# MCU_CPSW0_NUSS_CPTS_ register map
Vendor: Texas Instruments
Peripheral module from a debugger description file (folder am65x).
Registers are 32-bit, read-write, reset 0x0 unless marked. A register's access mark holds for its fields unless they carry their own. Offsets are as the file gives them; lines under a group give offsets from that group; [hi:lo] are bit positions; {n}, {i} and the like mark numbered series; 'fields as' and 'values as' point back to an identical list; <NAME> marks a mode.

## MCU_CPSW0_NUSS_CPTS
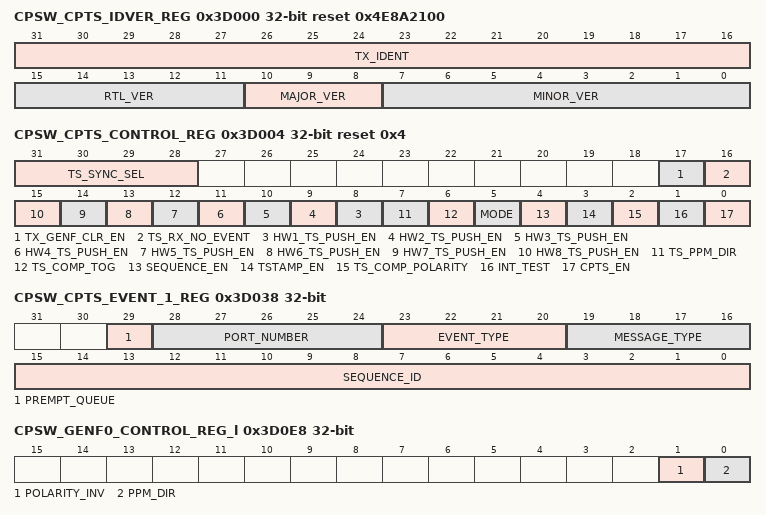
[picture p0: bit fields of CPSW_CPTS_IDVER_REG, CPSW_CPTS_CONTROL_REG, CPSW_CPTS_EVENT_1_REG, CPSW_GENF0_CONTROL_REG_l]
0x3D000 CPSW_CPTS_IDVER_REG ro reset 0x4E8A2100 (reset mask 0xFFFFFF00) — MCU_CPSW0_NUSS_CPTS Identification and Version Register
  [31:16] TX_IDENT — TX Identification Value
  [15:11] RTL_VER — RTL version value
  [10:8] MAJOR_VER — Major Version Value
  [7:0] MINOR_VER — Minor Version Value SR2.0: Bh SR1.0: 9h
0x3D004 CPSW_CPTS_CONTROL_REG reset 0x4 — Time Sync Control Register
  [31:28] TS_SYNC_SEL — TS_SYNC output time stamp counter bit select
  [17] TX_GENF_CLR_EN — GENF (and ESTF) Clear Enable. 0 = A TS_GENFn output is not cleared when the associated 1 = A TS_GENFn output is cleared when the associated
  [16] TS_RX_NO_EVENT — Timestamp Ethernet Receive produces no events. 0 = Ethernet receive timesync events enabled 1 = Ethernet receive timesync events disabled
  [n+7] HW{n}_TS_PUSH_EN (n=1..8) — Hardware push {n} enable
  [7] TS_PPM_DIR — PPM Correction Direction
  [6] TS_COMP_TOG — Time stamp Compare Toggle mode
  [5] MODE — 64-Bit Mode.
  [4] SEQUENCE_EN — Sequence Enable.
  [3] TSTAMP_EN — Host Receive time stamp Enable
  [2] TS_COMP_POLARITY
  [1] INT_TEST — Interrupt Test.
  [0] CPTS_EN — Time Sync Enable.
0x3D008 CPSW_CPTS_RFTCLK_SEL_REG — Added RFTCLK_SEL Register Bit Field Description Reference Clock Select Register
  [4:0] RFTCLK_SEL — Reference clock select. This bit field is used to control an external multiplexer that selects one out of 8 clocks for time sync reference. 0h = Selects CPSWHSDIV_CLKOUT2 clock 1h = Selects MAINHSDIV_CLKOUT3 clock 2h = Selects MCU_CPTS0_RFT_CLK I/O pin 3h = Selects CPTS0_RFT_CLK I/O pin 4h = Selects MCU_EXT_REFCLK0 I/O pin 5h = Selects EXT_REFCLK1 I/O pin 6h = Selects PCIE0_TXI0_CLK clock 7h = Selects PCIE1_TXI0_CLK clock The RFTCLK_SEL value can be written only when the [0] CPTS_EN and [3] TSTAMP_EN bits are cleared to zero in the
0x3D00C CPSW_CPTS_TS_PUSH_REG wo — Time Stamp Event Push Register
  [0] TS_PUSH — Time stamp event push.
0x3D010 CPSW_CPTS_TS_LOAD_VAL_REG — Time Stamp Load Low Value (lower 32-bits) Register
  [31:0] TS_LOAD_VAL — Time Stamp Load Low Value.
0x3D014 CPSW_CPTS_TS_LOAD_EN_REG wo — Time Stamp Load Enable Register
  [0] TS_LOAD_EN — Time Stamp Load.
0x3D018 CPSW_CPTS_TS_COMP_VAL_REG — Time Stamp Comparison Low Value (lower 32-bits) Register
  [31:0] TS_COMP_VAL — Time Stamp Comparison Low Value.
0x3D01C CPSW_CPTS_TS_COMP_LEN_REG — Time Stamp Comparison Length Register
  [31:0] TS_COMP_LENGTH — Time Stamp Comparison Length.
0x3D020 CPSW_CPTS_INTSTAT_RAW_REG — Interrupt Status Raw Register
  [0] TS_PEND_RAW — TS_PEND_RAW int read (before enable).
0x3D024 CPSW_CPTS_INTSTAT_MASKED_REG ro — Interrupt Status Masked Register
  [0] TS_PEND — TS_PEND masked interrupt read (after enable).
0x3D028 CPSW_CPTS_INT_ENABLE_REG — Interrupt Enable Register Register
  [0] TS_PEND_EN — TS_PEND masked interrupt enable.
0x3D02C CPSW_CPTS_TS_COMP_NUDGE_REG — Time Stamp Comparison Nudge Value Register
  [7:0] NUDGE — Time stamp Comparison Nudge Value.
0x3D030 CPSW_CPTS_EVENT_POP_REG wo — Event Interrupt Pop Register
  [0] EVENT_POP
0x3D034 CPSW_CPTS_EVENT_0_REG ro — Lower 32-bits of the Event Value Register
  [31:0] TIME_STAMP
0x3D038 CPSW_CPTS_EVENT_1_REG ro — Lower Middle 32-bits of the Event Value Register
  [29] PREMPT_QUEUE
  [28:24] PORT_NUMBER
  [23:20] EVENT_TYPE — Time Sync Event Type
  [19:16] MESSAGE_TYPE
  [15:0] SEQUENCE_ID
0x3D03C CPSW_CPTS_EVENT_2_REG ro — Upper Middle 32-bits of the Event Value Register
  [7:0] DOMAIN
0x3D040 CPSW_CPTS_EVENT_3_REG ro — Upper 32-bits of the Event Value Register
  [31:0] TIME_STAMP
0x3D044 CPSW_CPTS_TS_LOAD_HIGH_VAL_REG — Time Stamp Load High Value (upper 32-bits) Register
  [31:0] TS_LOAD_VAL — Time Stamp Load high Value.
0x3D048 CPSW_CPTS_TS_COMP_HIGH_VAL_REG — Time Stamp Comparison High Value (upper 32-bits) Register
  [31:0] TS_COMP_HIGH_VAL — Time Stamp Comparison High Value.
0x3D04C CPSW_CPTS_TS_ADD_VAL_REG — Time Stamp Add Value Register
  [2:0] ADD_VAL — The ts_add_value[2:0] is added to 1 to comprise the time stamp increment value.
0x3D050 CPSW_CPTS_TS_PPM_LOW_VAL_REG — Time Stamp PPM Load Low Value (lower 32-bits) Register
  [31:0] TS_PPM_LOW_VAL — Time Stamp PPM Low Value.
0x3D054 CPSW_CPTS_TS_PPM_HIGH_VAL_REG — Time Stamp PPM Load High Value (upper 32-bits) Register
  [9:0] TS_PPM_HIGH_VAL — Time Stamp PPM High Value.
0x3D058 CPSW_CPTS_TS_NUDGE_VAL_REG — Time Stamp Nudge Value Register
  [7:0] TS_NUDGE_VAL — Time Stamp Nudge Value.
0x3D0E0 CPSW_GENF0_COMP_LOW_REG_l — GENF0 time stamp Comparison Value Lower 32-bits Registers Offset = 0003D0E0h + (l * 20h); where l = 0 to 1
  [31:0] COMP_LOW — GENFn comparison value lower 32-bits.
0x3D0E4 CPSW_GENF0_COMP_HIGH_REG_l — GENF0 time stamp Comparison Value Upper 32-bits Registers Offset = 0003D0E4h + (l * 20h); where l = 0 to 1
  [31:0] COMP_HIGH — GENFn comparison value upper 32-bits.
0x3D0E8 CPSW_GENF0_CONTROL_REG_l — GENF0 Control Register Registers Offset = 0003D0E8h + (l * 20h); where l = 0 to 1
  [1] POLARITY_INV — Generate function N Polarity
  [0] PPM_DIR — Generate function N PPM direction.
0x3D0EC CPSW_GENF0_LENGTH_REG_l — GENF0 Length Value Registers Offset = 0003D0ECh + (l * 20h); where l = 0 to 1
  [31:0] LENGTH — Time Stamp Generate Function Length Value.
0x3D0F0 CPSW_GENF0_PPM_LOW_REG_l — GENF0 PPM Value Lower 32-bits Registers Offset = 0003D0F0h + (l * 20h); where l = 0 to 1
  [31:0] PPM_LOW — GENFn PPM Low Value.
0x3D0F4 CPSW_GENF0_PPM_HIGH_REG_l — GENF0 PPM Value Upper 32-bits Registers Offset = 0003D0F4h + (l * 20h); where l = 0 to 1
  [9:0] PPM_HIGH — GENFn PPM High Value.
0x3D0F8 CPSW_GENF0_NUDGE_REG_l — GENF0 Nudge Value Registers Offset = 0003D0F8h + (l * 20h); where l = 0 to 1.
  [7:0] NUDGE — GENFn Nudge Value.
0x3D200 CPSW_ESTF1_COMP_LOW_REG — ESTF1 Time Stamp Comparison Value Lower 32-bits Register.
  [31:0] COMP_LOW — ESTFn comparison value lower 32-bits.
0x3D204 CPSW_ESTF1_COMP_HIGH_REG — ESTF1 Time Stamp Comparison Value Upper 32-bits Register.
  [31:0] COMP_HIGH — ESTFn comparison value upper 32-bits.
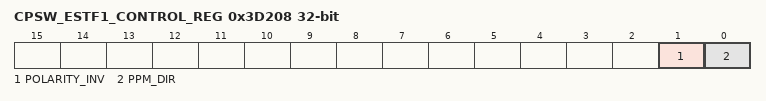
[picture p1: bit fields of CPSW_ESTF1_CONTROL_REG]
0x3D208 CPSW_ESTF1_CONTROL_REG — ESTF1 Control Register.
  fields as CPSW_GENF0_CONTROL_REG_l
0x3D20C CPSW_ESTF1_LENGTH_REG — ESTF1 Length Value Register.
  [31:0] LENGTH — Time Stamp ESTF Generate Function Length Value.
0x3D210 CPSW_ESTF1_PPM_LOW_REG — ESTF1 PPM Value Lower 32-bits Register.
  [31:0] PPM_LOW — ESTFn PPM Low Value.
0x3D214 CPSW_ESTF1_PPM_HIGH_REG — ESTF1 PPM Value Upper 32-bits Register.
  [9:0] PPM_HIGH — ESTFn PPM High Value.
0x3D218 CPSW_ESTF1_NUDGE_REG — ESTF1 Nudge Value Register.
  [7:0] NUDGE — ESTFn Nudge Value.
